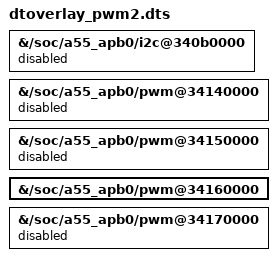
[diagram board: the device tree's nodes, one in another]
/dts-v1/;
/plugin/;

/ {
  fragment@0 {
    target-path = "/soc/a55_apb0/i2c@340b0000";
    __overlay__ {

      status = "disabled";

    };
  };

  fragment@1 {
    target-path = "/soc/a55_apb0/pwm@34140000";
    __overlay__ {

      status = "disabled";

    };
  };

  fragment@2 {
    target-path = "/soc/a55_apb0/pwm@34150000";
    __overlay__ {

      status = "disabled";

    };
  };

  fragment@3 {
    target-path = "/soc/a55_apb0/pwm@34160000";
    __overlay__ {

      status = "okay";

    };
  };

  fragment@4 {
    target-path = "/soc/a55_apb0/pwm@34170000";
    __overlay__ {

      status = "disabled";

    };
  };

};

